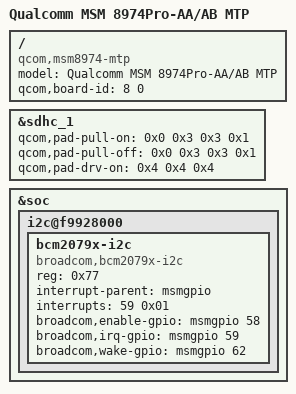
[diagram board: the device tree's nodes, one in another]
/* Copyright (c) 2013-2014, The Linux Foundation. All rights reserved.
 * Copyright (C) 2015 XiaoMi, Inc.
 *
 * This program is free software; you can redistribute it and/or modify
 * it under the terms of the GNU General Public License version 2 and
 * only version 2 as published by the Free Software Foundation.
 *
 * This program is distributed in the hope that it will be useful,
 * but WITHOUT ANY WARRANTY; without even the implied warranty of
 * MERCHANTABILITY or FITNESS FOR A PARTICULAR PURPOSE.  See the
 * GNU General Public License for more details.
 */

/dts-v1/;

/include/ "msm8974pro-ab-pm8941.dtsi"
/include/ "msm8974-mtp.dtsi"

/ {
	model = "Qualcomm MSM 8974Pro-AA/AB MTP";
	compatible = "qcom,msm8974-mtp", "qcom,msm8974", "qcom,mtp";
	qcom,board-id = <8 0>;
};

&sdhc_1 {
	qcom,pad-pull-on = <0x0 0x3 0x3 0x1>; /* no-pull, pull-up, pull-up, pull-down */
	qcom,pad-pull-off = <0x0 0x3 0x3 0x1>; /* no-pull, pull-up, pull-up, pull-down */
	qcom,pad-drv-on = <0x4 0x4 0x4>; /* 10mA, 10mA, 10mA */
};

&soc {
	i2c@f9928000 {
		bcm2079x-i2c {
			compatible = "broadcom,bcm2079x-i2c";
			reg = <0x77>;
			interrupt-parent = <&msmgpio>;
			interrupts = <59 0x01>;
			broadcom,enable-gpio = <&msmgpio 58 0x00>;
			broadcom,irq-gpio = <&msmgpio 59 0x00>;
			broadcom,wake-gpio = <&msmgpio 62 0x00>;
		};
	};
};
